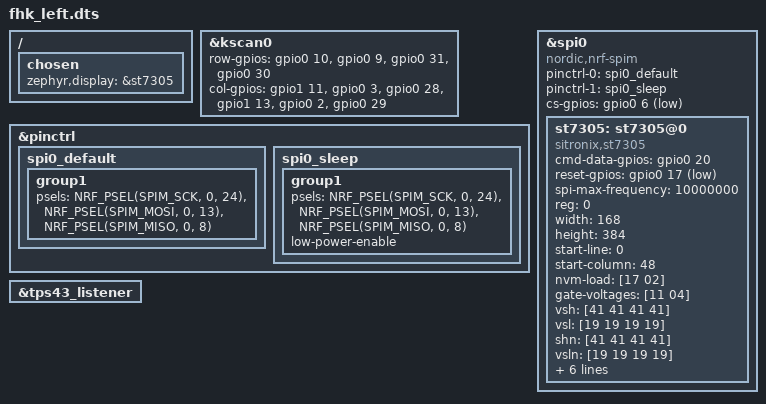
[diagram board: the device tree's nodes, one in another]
/*
*
* Copyright (c) 2024 The ZMK Contributors
* SPDX-License-Identifier: MIT
*
*/

#include "fhk.dtsi"

&kscan0 {
    row-gpios
        = <&gpio0 10 (GPIO_ACTIVE_HIGH | GPIO_PULL_DOWN)>
        , <&gpio0 9 (GPIO_ACTIVE_HIGH | GPIO_PULL_DOWN)>
        , <&gpio0 31 (GPIO_ACTIVE_HIGH | GPIO_PULL_DOWN)>
        , <&gpio0 30 (GPIO_ACTIVE_HIGH | GPIO_PULL_DOWN)>
        ;
    col-gpios
        = <&gpio1 11 GPIO_ACTIVE_HIGH>
        , <&gpio0 3 GPIO_ACTIVE_HIGH>
        , <&gpio0 28 GPIO_ACTIVE_HIGH>
        , <&gpio1 13 GPIO_ACTIVE_HIGH>
        , <&gpio0 2 GPIO_ACTIVE_HIGH>
        , <&gpio0 29 GPIO_ACTIVE_HIGH>
        ;
};

&pinctrl {
    spi0_default: spi0_default {
        group1 {
            psels = <NRF_PSEL(SPIM_SCK, 0, 24)>,
                <NRF_PSEL(SPIM_MOSI, 0, 13)>,
                <NRF_PSEL(SPIM_MISO, 0, 8)>;
        };
    };

    spi0_sleep: spi0_sleep {
        group1 {
            psels = <NRF_PSEL(SPIM_SCK, 0, 24)>,
                <NRF_PSEL(SPIM_MOSI, 0, 13)>,
                <NRF_PSEL(SPIM_MISO, 0, 8)>;
            low-power-enable;
        };
    };
};

st7305_spi: &spi0 {
    compatible = "nordic,nrf-spim";
    pinctrl-0 = <&spi0_default>;
    pinctrl-1 = <&spi0_sleep>;
    pinctrl-names = "default", "sleep";
    cs-gpios = <&gpio0 6 GPIO_ACTIVE_LOW>;
    st7305: st7305@0 {
        compatible = "sitronix,st7305";
        cmd-data-gpios = <&gpio0 20 GPIO_ACTIVE_HIGH>;
	    reset-gpios = <&gpio0 17 GPIO_ACTIVE_LOW>;
        spi-max-frequency = <10000000>;
        reg = <0>;
        width = <168>;
		height = <384>;
		start-line = <0>;
		start-column = <48>;
        nvm-load = [17 02];
        gate-voltages = [11 04];
        vsh = [41 41 41 41];
    	vsl = [19 19 19 19];
    	shn = [41 41 41 41];
    	vsln = [19 19 19 19];
        osc-settings = <0xA6>;
    	framerate = <0x5>;
		multiplex-ratio = <0x64>;
    	source-voltage = <0x0>;
		remap-value = <0x40>;
	    panel-settings = <0x29>;  
    };
};  

/ {
    chosen {
        zephyr,display = &st7305;
    };    
};

&tps43_listener {
    status = "okay";
};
